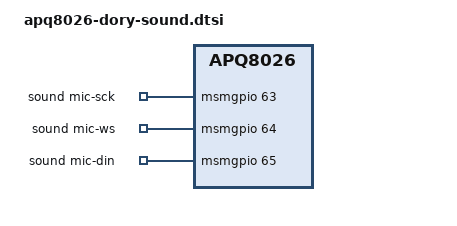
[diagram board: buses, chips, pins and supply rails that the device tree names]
/* Copyright (c) 2012, Code Aurora Forum. All rights reserved.
 *
 * This program is free software; you can redistribute it and/or modify
 * it under the terms of the GNU General Public License version 2 and
 * only version 2 as published by the Free Software Foundation.
 *
 * This program is distributed in the hope that it will be useful,
 * but WITHOUT ANY WARRANTY; without even the implied warranty of
 * MERCHANTABILITY or FITNESS FOR A PARTICULAR PURPOSE.  See the
 * GNU General Public License for more details.
 */

&soc {
	sound {
		compatible = "dory,dory-mi2s-audio";
		dory,model = "dory-mi2s-snd-card";

		dory,mic-sck-gpio = <&msmgpio 63 0x00>;
		dory,mic-ws-gpio = <&msmgpio 64 0x00>;
		dory,mic-din-gpio = <&msmgpio 65 0x00>;
		dory,mic-supply = <&pm8226_l23>;
	};

	slim@fe12f000 {
		compatible = "qcom,slim-ngd";
		status = "disabled";
	};
};
